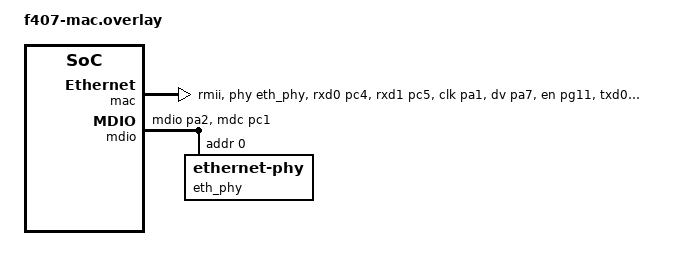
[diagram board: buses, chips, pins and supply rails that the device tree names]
&mac {
	status = "okay";
	pinctrl-0 = <&eth_rxd0_pc4 &eth_rxd1_pc5 &eth_ref_clk_pa1 &eth_crs_dv_pa7 &eth_tx_en_pg11 &eth_txd0_pg13 &eth_txd1_pg14>;
	pinctrl-names = "default";
	phy-connection-type = "rmii";
	phy-handle = <&eth_phy>;
};

&mdio {
	status = "okay";
	pinctrl-0 = <&eth_mdio_pa2 &eth_mdc_pc1>;
	pinctrl-names = "default";

	eth_phy: ethernet-phy@0 {
		compatible = "ethernet-phy";
		reg = <0x00>;
	};
};

